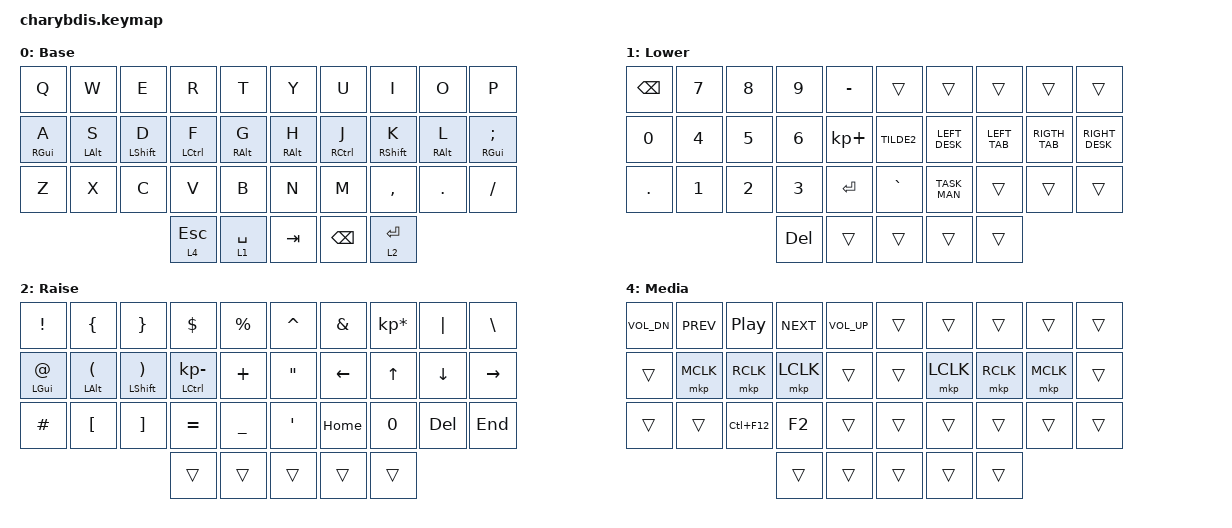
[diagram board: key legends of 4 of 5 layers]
#include <behaviors.dtsi>
#include <dt-bindings/zmk/keys.h>
#include <dt-bindings/zmk/bt.h>
#include <dt-bindings/zmk/mouse.h>

#include <dt-bindings/zmk/input_transform.h>

#define DEFAULT 0
#define LOWER   1
#define RAISE   2
#define ADJUST  3
#define MEDIA   4
#define LEFT_DESK LG(LC(LEFT))
#define RIGHT_DESK LG(LC(RIGHT))
#define TASK_MAN LC(LS(ESC))
#define LEFT_TAB LA(LS(TAB))
#define RIGTH_TAB LA(TAB)
#define IMPL LC(F12)

&mt {
    tapping-term-ms = <140>;
    flavor = "tap-preferred";
};

/ {
    trackball_listener {
        compatible = "zmk,input-listener";
        device = <&vtrackball>;
        
        scroll {
            layers = <LOWER>;
            input-processors = <&xy_invert (INPUT_TRANSFORM_Y_INVERT)>, <&xy_scaler 1 8>, <&x_scaler 0 1>, <&mouse_to_wheel_mapper>;
        };
    };

    xy_scaler: xy_scaler {
        compatible = "zmk,input-processor-scaler";
        #input-processor-cells = <2>;
        type = <INPUT_EV_REL>;
        codes = <INPUT_REL_X>, <INPUT_REL_Y>;
    };

    x_scaler: x_scaler {
        compatible = "zmk,input-processor-scaler";
        #input-processor-cells = <2>;
        type = <INPUT_EV_REL>;
        codes = <INPUT_REL_X>;
    };

    y_scaler: y_scaler {
        compatible = "zmk,input-processor-scaler";
        #input-processor-cells = <2>;
        type = <INPUT_EV_REL>;
        codes = <INPUT_REL_Y>;
    };

    xy_invert: xy_invert {
        compatible = "zmk,input-processor-transform";
        #input-processor-cells = <1>;
        type = <INPUT_EV_REL>;
        x-codes = <INPUT_REL_X>, <INPUT_REL_WHEEL>;
        y-codes = <INPUT_REL_Y>, <INPUT_REL_HWHEEL>;
    };

    mouse_to_wheel_mapper: mouse_to_wheel_mapper {
        compatible = "zmk,input-processor-code-mapper";
        #input-processor-cells = <0>;
        type = <INPUT_EV_REL>;
        map = <INPUT_REL_X INPUT_REL_MISC>, <INPUT_REL_Y INPUT_REL_WHEEL>;
    };

    chosen {
        zmk,matrix_transform = &five_column_transform;
    };

    keymap {
        compatible = "zmk,keymap";

        Base {
                        bindings = <
        &kp Q       &kp W       &kp E          &kp R            &kp T           &kp Y           &kp U            &kp I        &kp O       &kp P
        &mt RGUI A  &mt LALT S  &mt LSHFT D    &mt LCTRL F      &mt RALT G      &mt RALT H      &mt RCTRL J      &mt RSHFT K  &mt RALT L  &mt RGUI SEMI
        &kp Z       &kp X       &kp C          &kp V            &kp B           &kp N           &kp M            &kp COMMA    &kp DOT     &kp FSLH
                                        &lt 4 ESC  &lt 1 SPACE  &kp TAB         &kp BSPC        &lt 2 ENTER
            >;
        };

        Lower {
                        bindings = <
        &kp BSPC  &kp N7  &kp N8   &kp N9           &kp MINUS      &trans      &trans           &trans    &trans  &trans
        &kp N0    &kp N4  &kp N5   &kp N6           &kp KP_PLUS    &kp TILDE2  &kp LEFT_DESK    &kp LEFT_TAB    &kp RIGTH_TAB  &kp RIGHT_DESK 
        &kp DOT   &kp N1  &kp N2   &kp N3           &kp ENTER      &kp GRAVE   &kp TASK_MAN     &trans    &trans  &trans 
                                &kp DEL  &trans  &trans        &trans    &trans
            >;
        };

        Raise {
                        bindings = <
        &kp EXCL     &kp LBRC       &kp RBRC        &kp DLLR            &kp PRCNT    &kp CARET  &kp AMPS         &kp KP_MULTIPLY  &kp PIPE  &kp BSLH  
        &mt LGUI AT  &mt LALT LPAR  &mt LSHFT RPAR  &mt LCTRL KP_MINUS  &kp PLUS     &kp DQT    &kp LEFT         &kp UP           &kp DOWN  &kp RIGHT 
        &kp HASH     &kp LBKT       &kp RBKT        &kp EQUAL           &kp UNDER    &kp APOS   &kp HOME         &kp N0           &kp DEL   &kp END
                                            &trans   &trans     &trans      &trans  &trans
            >;
        };

        Adjust {
                        bindings = <
        &trans        &trans         &trans           &trans        &trans    &kp F7           &kp F8    &kp F9  &kp F12  
        &bt BT_SEL 3  &bt BT_SEL 4   &trans           &trans        &trans    &kp F4           &kp F5    &kp F6  &kp F11 
        &bt BT_SEL 0  &bt BT_SEL 1   &bt BT_SEL 2     &bt BT_CLR    &trans    &kp F1           &kp F2    &kp F3  &kp F10 
                                    &trans  &trans  &trans       &trans  &trans 
            >;
        };

        Media {
                        bindings = <
        &kp C_VOL_DN  &kp C_PREV  &kp C_PLAY_PAUSE  &kp C_NEXT          &kp C_VOL_UP    &trans    &trans           &trans    &trans     &trans 
        &trans        &mkp MCLK   &mkp RCLK         &mkp LCLK           &trans          &trans    &mkp LCLK        &mkp RCLK &mkp MCLK  &trans 
        &trans        &trans      &kp LC(F12)       &kp F2              &trans          &trans    &trans           &trans    &trans     &trans 
                                        &trans     &trans  &trans               &trans  &trans
            >;
        };
    };

    conditional_layers {
        compatible = "zmk,conditional-layers";
        tri_layer {
            if-layers = <1 2>;
            then-layer = <3>;
        };
    };
};
